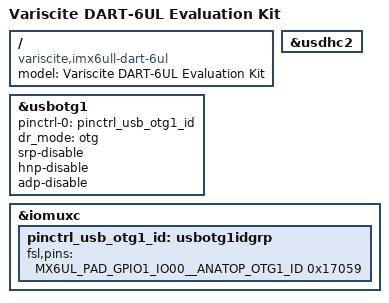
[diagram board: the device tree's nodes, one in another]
// SPDX-License-Identifier: GPL-2.0+
/*
 * Copyright (C) 2019 Parthiban Nallathambi <parthitce@gmail.com>
 */

/dts-v1/;

#include "imx6ull.dtsi"
#include "imx6ull-dart-6ul.dtsi"

/ {
	model = "Variscite DART-6UL Evaluation Kit";
	compatible = "variscite,imx6ull-dart-6ul", "fsl,imx6ull";
};

&usdhc2 {
	status = "okay";
};

&usbotg1 {
	pinctrl-names = "default";
	pinctrl-0 = <&pinctrl_usb_otg1_id>;
	dr_mode = "otg";
	srp-disable;
	hnp-disable;
	adp-disable;
	status = "okay";
};

&iomuxc {
	pinctrl-names = "default";

	pinctrl_usb_otg1_id: usbotg1idgrp {
		fsl,pins = <
			MX6UL_PAD_GPIO1_IO00__ANATOP_OTG1_ID    0x17059
		>;
	};

};
